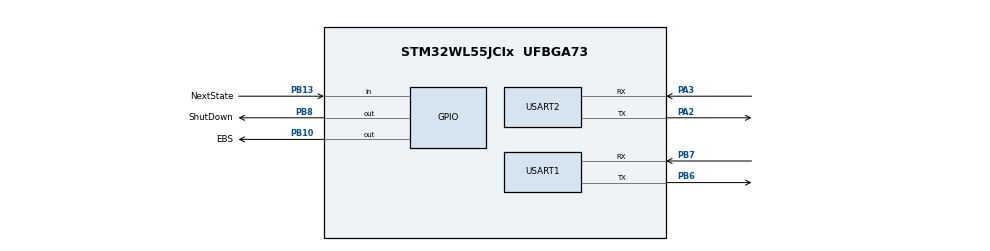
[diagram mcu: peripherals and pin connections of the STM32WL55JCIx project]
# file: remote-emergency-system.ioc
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Mcu.Family=STM32WL
Mcu.Name=STM32WL55JCIx
Mcu.Package=UFBGA73
NVIC.PriorityGroup=NVIC_PRIORITYGROUP_4
NVIC.SUBGHZ_Radio_IRQn=true\:0\:0\:false\:false\:true\:true\:true\:true
PA2.Mode=Asynchronous
PA2.Signal=USART2_TX
PA3.Mode=Asynchronous
PA3.Signal=USART2_RX
PB10.GPIO_Label=EBS
PB10.Signal=GPIO_Output
PB13.GPIO_Label=NextState
PB13.Signal=GPIO_Input
PB6.Mode=Asynchronous
PB6.Signal=USART1_TX
PB7.Mode=Asynchronous
PB7.Signal=USART1_RX
PB8.GPIO_Label=ShutDown
PB8.Signal=GPIO_Output
PC13.Signal=RTC_TS
ProjectManager.HeapSize=0x200
ProjectManager.StackSize=0x400
ProjectManager.TargetToolchain=STM32CubeIDE
RCC.AHBFreq_Value=48000000
RCC.APB1Freq_Value=48000000
RCC.APB1TimFreq_Value=48000000
RCC.APB2Freq_Value=48000000
RCC.APB2TimFreq_Value=48000000
RCC.APB3Freq_Value=48000000
RCC.CortexFreq_Value=48000000
RCC.HCLKFreq_Value=48000000
RCC.HSE_VALUE=8000000
RCC.HSI_VALUE=16000000
RCC.LSE_VALUE=32768
RCC.MSIClockRange=RCC_MSIRANGE_11
RCC.SYSCLKFreq_VALUE=48000000
RCC.VCOOutputFreq_Value=384000000
TIM1.Period=47999 + 1 
USART1.VirtualMode-Asynchronous=VM_ASYNC
USART2.VirtualMode-Asynchronous=VM_ASYNC
VP_SUBGHZ_VS_SUBGHZ.Mode=SUBGHZ_Activate
VP_TIM1_VS_ClockSourceINT.Mode=Internal
board=custom

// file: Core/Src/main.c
/* USER CODE BEGIN Header */
/**
  ******************************************************************************
  * @file           : main.c
  * @brief          : Main program body
  ******************************************************************************
  * @attention
  *
  * Copyright (c) 2025 STMicroelectronics.
  * All rights reserved.
  *
  * This software is licensed under terms that can be found in the LICENSE file
  * in the root directory of this software component.
  * If no LICENSE file comes with this software, it is provided AS-IS.
  *
  ******************************************************************************
  */
/* USER CODE END Header */
#include "main.h"
#include "subghz.h"
#include "tim.h"
#include "usart.h"
#include "gpio.h"

/* USER CODE BEGIN Includes */
#include "mainLoRa.h";
/* USER CODE END Includes */

void SystemClock_Config(void);

int main(void)
{

  /* MCU Configuration--------------------------------------------------------*/

  /* Reset of all peripherals, Initializes the Flash interface and the Systick. */
  HAL_Init();

  /* Configure the system clock */
  SystemClock_Config();

  /* Initialize all configured peripherals */
  MX_GPIO_Init();
  MX_SUBGHZ_Init();
  MX_USART2_UART_Init();
  MX_TIM1_Init();
  MX_USART1_UART_Init();

  /* Infinite loop */
  while (1)
  {

    /* USER CODE BEGIN 3 */
	  mainLoRa();
  }
  /* USER CODE END 3 */
}

void SystemClock_Config(void)
{
  RCC_OscInitTypeDef RCC_OscInitStruct = {0};
  RCC_ClkInitTypeDef RCC_ClkInitStruct = {0};

  /** Configure the main internal regulator output voltage
  */
  __HAL_PWR_VOLTAGESCALING_CONFIG(PWR_REGULATOR_VOLTAGE_SCALE1);

  /** Initializes the CPU, AHB and APB buses clocks
  */
  RCC_OscInitStruct.OscillatorType = RCC_OSCILLATORTYPE_MSI;
  RCC_OscInitStruct.MSIState = RCC_MSI_ON;
  RCC_OscInitStruct.MSICalibrationValue = RCC_MSICALIBRATION_DEFAULT;
  RCC_OscInitStruct.MSIClockRange = RCC_MSIRANGE_11;
  RCC_OscInitStruct.PLL.PLLState = RCC_PLL_NONE;
  if (HAL_RCC_OscConfig(&RCC_OscInitStruct) != HAL_OK)
  {
    Error_Handler();
  }

  /** Configure the SYSCLKSource, HCLK, PCLK1 and PCLK2 clocks dividers
  */
  RCC_ClkInitStruct.ClockType = RCC_CLOCKTYPE_HCLK3|RCC_CLOCKTYPE_HCLK
                              |RCC_CLOCKTYPE_SYSCLK|RCC_CLOCKTYPE_PCLK1
                              |RCC_CLOCKTYPE_PCLK2;
  RCC_ClkInitStruct.SYSCLKSource = RCC_SYSCLKSOURCE_MSI;
  RCC_ClkInitStruct.AHBCLKDivider = RCC_SYSCLK_DIV1;
  RCC_ClkInitStruct.APB1CLKDivider = RCC_HCLK_DIV1;
  RCC_ClkInitStruct.APB2CLKDivider = RCC_HCLK_DIV1;
  RCC_ClkInitStruct.AHBCLK3Divider = RCC_SYSCLK_DIV1;

  if (HAL_RCC_ClockConfig(&RCC_ClkInitStruct, FLASH_LATENCY_2) != HAL_OK)
  {
    Error_Handler();
  }
}

void Error_Handler(void)
{
  __disable_irq();
  while (1)
  {
  }
}
